# ATmega162 register map
Vendor: Atmel; File version: 1.0
CPU: other r0p0, little endian, no MPU, no FPU, 4 interrupt priority bits
Registers are 8-bit, read-write, reset 0x0 unless marked. A register's access mark holds for its fields unless they carry their own. Offsets are from the block's base; [hi:lo] are bit positions.

## TC3 — Timer/Counter, 16-bit
Base 0x0080007C
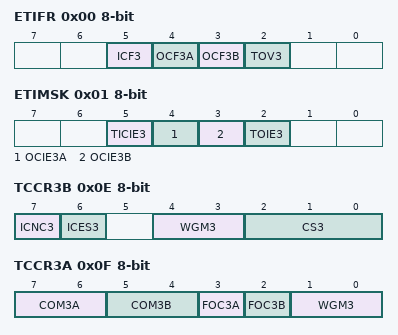
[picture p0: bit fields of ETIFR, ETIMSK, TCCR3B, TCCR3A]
0x00 ETIFR — Extended Timer/Counter Interrupt Flag register (read-only for debugger)
  [5] ICF3 — Input Capture Flag 3
  [4] OCF3A — Output Compare Flag 3A
  [3] OCF3B — Output Compare Flag 3B
  [2] TOV3 — Timer/Counter3 Overflow Flag
0x01 ETIMSK — Extended Timer/Counter Interrupt Mask Register
  [5] TICIE3 — Timer/Counter3 Input Capture Interrupt Enable
  [4] OCIE3A — Timer/Counter3 Output CompareA Match Interrupt Enable
  [3] OCIE3B — Timer/Counter3 Output CompareB Match Interrupt Enable
  [2] TOIE3 — Timer/Counter3 Overflow Interrupt Enable
0x04 ICR3 16-bit (reset mask 0xFF) — Timer/Counter3 Input Capture Register Bytes
0x08 OCR3B 16-bit (reset mask 0xFF) — Timer/Counter3 Output Compare Register B Bytes
0x0A OCR3A 16-bit (reset mask 0xFF) — Timer/Counter3 Output Compare Register A Bytes
0x0C TCNT3 16-bit (reset mask 0xFF) — Timer/Counter3 Bytes
0x0E TCCR3B — Timer/Counter3 Control Register B
  [7] ICNC3 — Input Capture 3 Noise Canceler
  [6] ICES3 — Input Capture 3 Edge Select
  [4:3] WGM3 — Pulse Width Modulator Select Bits
  [2:0] CS3 — Clock Select3 bits
    0=NO_CLOCK_SOURCE_STOPPED; 1=RUNNING_NO_PRESCALING; 2=RUNNING_CLK_8; 3=RUNNING_CLK_64; 4=RUNNING_CLK_256; 5=RUNNING_CLK_1024; 6=RUNNING_CLK_16; 7=RUNNING_CLK_32
0x0F TCCR3A — Timer/Counter3 Control Register A
  [7:6] COM3A — Compare Output Mode 3A, bits
  [5:4] COM3B — Compare Output Mode 3B, bits
  [3] FOC3A — Force Output Compare for Channel A
  [2] FOC3B — Force Output Compare for Channel B
  [1:0] WGM3 — Pulse Width Modulator Select Bits

## USART0 — USART
Base 0x00800029
0x00 UBRR0L — USART Baud Rate Register Low Byte
  [7:0] UBRR0 — USART Baud Rate Register Low bits
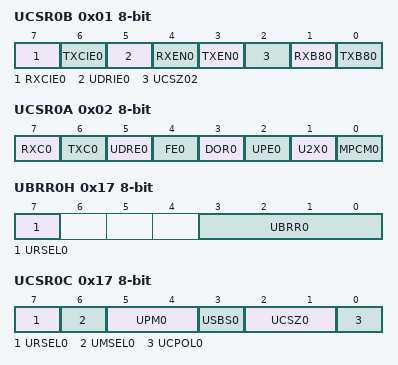
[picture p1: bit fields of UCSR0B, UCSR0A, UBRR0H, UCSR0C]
0x01 UCSR0B — USART Control and Status Register B
  [7] RXCIE0 — RX Complete Interrupt Enable
  [6] TXCIE0 — TX Complete Interrupt Enable
  [5] UDRIE0 — USART Data register Empty Interrupt Enable
  [4] RXEN0 — Receiver Enable
  [3] TXEN0 — Transmitter Enable
  [2] UCSZ02 — Character Size
  [1] RXB80 — Receive Data Bit 8
  [0] TXB80 — Transmit Data Bit 8
0x02 UCSR0A — USART Control and Status Register A (read-only for debugger)
  [7] RXC0 ro — USART Receive Complete
  [6] TXC0 — USART Transmit Complete
  [5] UDRE0 ro — USART Data Register Empty
  [4] FE0 ro — Framing Error
  [3] DOR0 ro — Data overRun
  [2] UPE0 ro — Parity Error
  [1] U2X0 — Double the USART transmission speed
  [0] MPCM0 — Multi-processor Communication Mode
0x03 UDR0 — USART I/O Data Register (write-only for debugger)
0x17 UBRR0H — USART Baud Rate Register High Byte
  [7] URSEL0 — Register Select
  [3:0] UBRR0 — USART Baud Rate Register High bits
0x17 UCSR0C — USART Control and Status Register C (write-only for debugger)
  [7] URSEL0 — Register Select
  [6] UMSEL0 — USART Mode Select
    0=ASYNCHRONOUS_OPERATION; 1=SYNCHRONOUS_OPERATION
  [5:4] UPM0 — Parity Mode Bits
    0=DISABLED; 2=ENABLED_EVEN_PARITY; 3=ENABLED_ODD_PARITY
  [3] USBS0 — Stop Bit Select
    0=1_BIT; 1=2_BIT
  [2:1] UCSZ0 — Character Size
  [0] UCPOL0 — Clock Polarity

## USART1 — USART
Base 0x00800020
0x00 UBRR1L — USART Baud Rate Register Low Byte
  [7:0] UBRR1 — USART Baud Rate Register Low bits
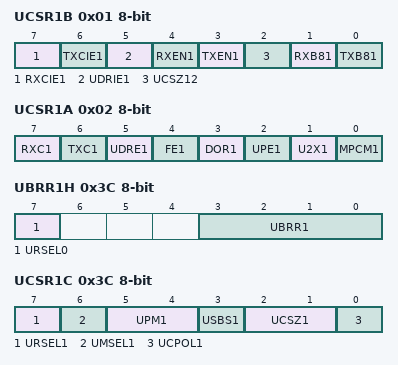
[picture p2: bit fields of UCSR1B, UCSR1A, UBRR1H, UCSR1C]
0x01 UCSR1B — USART Control and Status Register B
  [7] RXCIE1 — RX Complete Interrupt Enable
  [6] TXCIE1 — TX Complete Interrupt Enable
  [5] UDRIE1 — USART Data register Empty Interrupt Enable
  [4] RXEN1 — Receiver Enable
  [3] TXEN1 — Transmitter Enable
  [2] UCSZ12 — Character Size
  [1] RXB81 — Receive Data Bit 8
  [0] TXB81 — Transmit Data Bit 8
0x02 UCSR1A — USART Control and Status Register A (read-only for debugger)
  [7] RXC1 — USART Receive Complete
  [6] TXC1 — USART Transmit Complete
  [5] UDRE1 — USART Data Register Empty
  [4] FE1 — Framing Error
  [3] DOR1 — Data overRun
  [2] UPE1 — Parity Error
  [1] U2X1 — Double the USART transmission speed
  [0] MPCM1 — Multi-processor Communication Mode
0x03 UDR1 — USART I/O Data Register (write-only for debugger)
0x3C UBRR1H — USART Baud Rate Register High Byte
  [7] URSEL0 — Register Select
  [3:0] UBRR1 — USART Baud Rate Register High bits
0x3C UCSR1C — USART Control and Status Register C (write-only for debugger)
  [7] URSEL1 — Register Select
  [6] UMSEL1 — USART Mode Select
    0=ASYNCHRONOUS_OPERATION; 1=SYNCHRONOUS_OPERATION
  [5:4] UPM1 — Parity Mode Bits
    0=DISABLED; 2=ENABLED_EVEN_PARITY; 3=ENABLED_ODD_PARITY
  [3] USBS1 — Stop Bit Select
    0=1_BIT; 1=2_BIT
  [2:1] UCSZ1 — Character Size
  [0] UCPOL1 — Clock Polarity

## WDT — Watchdog Timer
Base 0x00800041
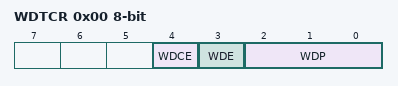
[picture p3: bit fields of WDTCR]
0x00 WDTCR — Watchdog Timer Control Register
  [4] WDCE — Watchdog Change Enable
  [3] WDE — Watch Dog Enable
  [2:0] WDP — Watch Dog Timer Prescaler bits
    0=OSCILLATOR_CYCLES_16K; 1=OSCILLATOR_CYCLES_32K; 2=OSCILLATOR_CYCLES_64K; 3=OSCILLATOR_CYCLES_128K; 4=OSCILLATOR_CYCLES_256K; 5=OSCILLATOR_CYCLES_512K; 6=OSCILLATOR_CYCLES_1024K; 7=OSCILLATOR_CYCLES_2048K
